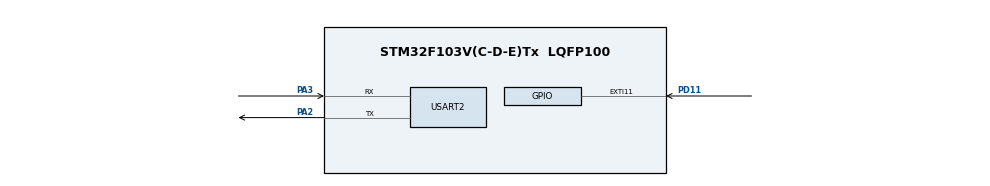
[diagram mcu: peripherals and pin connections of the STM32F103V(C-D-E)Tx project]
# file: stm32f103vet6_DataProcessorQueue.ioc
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FREERTOS.Tasks01=defaultTask,0,128,StartDefaultTask,Default,NULL,Dynamic,NULL,NULL;DataProcessorTa,0,256,StartDataProcessorTask,Default,NULL,Dynamic,NULL,NULL
Mcu.Family=STM32F1
Mcu.Name=STM32F103V(C-D-E)Tx
Mcu.Package=LQFP100
NVIC.EXTI15_10_IRQn=true\:5\:0\:true\:false\:true\:true\:true\:true\:true
NVIC.PriorityGroup=NVIC_PRIORITYGROUP_4
OSC_IN.Mode=HSE-External-Oscillator
OSC_IN.Signal=RCC_OSC_IN
OSC_OUT.Mode=HSE-External-Oscillator
OSC_OUT.Signal=RCC_OSC_OUT
PA13.Mode=Serial_Wire
PA13.Signal=SYS_JTMS-SWDIO
PA14.Mode=Serial_Wire
PA14.Signal=SYS_JTCK-SWCLK
PA2.Mode=Asynchronous
PA2.Signal=USART2_TX
PA3.Mode=Asynchronous
PA3.Signal=USART2_RX
PD11.GPIO_ModeDefaultEXTI=GPIO_MODE_IT_FALLING
PD11.GPIO_PuPd=GPIO_PULLUP
PD11.Signal=GPXTI11
ProjectManager.HeapSize=0x200
ProjectManager.StackSize=0x400
ProjectManager.TargetToolchain=STM32CubeIDE
RCC.APB1Freq_Value=8000000
RCC.APB2Freq_Value=8000000
USART2.VirtualMode=VM_ASYNC
VP_FREERTOS_VS_CMSIS_V1.Mode=CMSIS_V1
board=custom

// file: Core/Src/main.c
/* USER CODE BEGIN Header */
/**
  ******************************************************************************
  * @file           : main.c
  * @brief          : Main program body
  ******************************************************************************
  * @attention
  *
  * Copyright (c) 2026 STMicroelectronics.
  * All rights reserved.
  *
  * This software is licensed under terms that can be found in the LICENSE file
  * in the root directory of this software component.
  * If no LICENSE file comes with this software, it is provided AS-IS.
  *
  ******************************************************************************
  */
/* USER CODE END Header */
#include "main.h"
#include "cmsis_os.h"

/* USER CODE BEGIN Includes */
#include <stdio.h>
#include <string.h>
#include "queue.h"
#include "task.h"
/* USER CODE END Includes */

/* USER CODE BEGIN PTD */
typedef struct
{
    uint32_t event_id;
    uint32_t tick;
} ButtonEvent_t;
/* USER CODE END PTD */

UART_HandleTypeDef huart2;

osThreadId defaultTaskHandle;
osThreadId DataProcessorTaHandle;
/* USER CODE BEGIN PV */
QueueHandle_t ButtonQueueHandle;
volatile uint32_t g_eventCounter = 0;
/* USER CODE END PV */

void SystemClock_Config(void);
static void MX_GPIO_Init(void);
static void MX_USART2_UART_Init(void);
void StartDefaultTask(void const * argument);
void StartDataProcessorTask(void const * argument);

int main(void)
{

  /* MCU Configuration--------------------------------------------------------*/

  /* Reset of all peripherals, Initializes the Flash interface and the Systick. */
  HAL_Init();

  /* Configure the system clock */
  SystemClock_Config();

  /* Initialize all configured peripherals */
  MX_GPIO_Init();
  MX_USART2_UART_Init();

  /* Create the thread(s) */
  /* definition and creation of defaultTask */
  osThreadDef(defaultTask, StartDefaultTask, osPriorityNormal, 0, 128);
  defaultTaskHandle = osThreadCreate(osThread(defaultTask), NULL);

  /* definition and creation of DataProcessorTa */
  osThreadDef(DataProcessorTa, StartDataProcessorTask, osPriorityNormal, 0, 256);
  DataProcessorTaHandle = osThreadCreate(osThread(DataProcessorTa), NULL);

  /* USER CODE BEGIN RTOS_THREADS */
  /* add threads, ... */
  ButtonQueueHandle = xQueueCreate(10, sizeof(ButtonEvent_t));
  if (ButtonQueueHandle == NULL)
  {
      Error_Handler();
  }
  /* USER CODE END RTOS_THREADS */

  /* Start scheduler */
  osKernelStart();

  /* We should never get here as control is now taken by the scheduler */

  /* Infinite loop */
  while (1)
  {

  }
}

void SystemClock_Config(void)
{
  RCC_OscInitTypeDef RCC_OscInitStruct = {0};
  RCC_ClkInitTypeDef RCC_ClkInitStruct = {0};

  /** Initializes the RCC Oscillators according to the specified parameters
  * in the RCC_OscInitTypeDef structure.
  */
  RCC_OscInitStruct.OscillatorType = RCC_OSCILLATORTYPE_HSI;
  RCC_OscInitStruct.HSIState = RCC_HSI_ON;
  RCC_OscInitStruct.HSICalibrationValue = RCC_HSICALIBRATION_DEFAULT;
  RCC_OscInitStruct.PLL.PLLState = RCC_PLL_NONE;
  if (HAL_RCC_OscConfig(&RCC_OscInitStruct) != HAL_OK)
  {
    Error_Handler();
  }

  /** Initializes the CPU, AHB and APB buses clocks
  */
  RCC_ClkInitStruct.ClockType = RCC_CLOCKTYPE_HCLK|RCC_CLOCKTYPE_SYSCLK
                              |RCC_CLOCKTYPE_PCLK1|RCC_CLOCKTYPE_PCLK2;
  RCC_ClkInitStruct.SYSCLKSource = RCC_SYSCLKSOURCE_HSI;
  RCC_ClkInitStruct.AHBCLKDivider = RCC_SYSCLK_DIV1;
  RCC_ClkInitStruct.APB1CLKDivider = RCC_HCLK_DIV1;
  RCC_ClkInitStruct.APB2CLKDivider = RCC_HCLK_DIV1;

  if (HAL_RCC_ClockConfig(&RCC_ClkInitStruct, FLASH_LATENCY_0) != HAL_OK)
  {
    Error_Handler();
  }
}

static void MX_USART2_UART_Init(void)
{

  huart2.Instance = USART2;
  huart2.Init.BaudRate = 115200;
  huart2.Init.WordLength = UART_WORDLENGTH_8B;
  huart2.Init.StopBits = UART_STOPBITS_1;
  huart2.Init.Parity = UART_PARITY_NONE;
  huart2.Init.Mode = UART_MODE_TX_RX;
  huart2.Init.HwFlowCtl = UART_HWCONTROL_NONE;
  huart2.Init.OverSampling = UART_OVERSAMPLING_16;
  if (HAL_UART_Init(&huart2) != HAL_OK)
  {
    Error_Handler();
  }

}

static void MX_GPIO_Init(void)
{
  GPIO_InitTypeDef GPIO_InitStruct = {0};

  /* GPIO Ports Clock Enable */
  __HAL_RCC_GPIOA_CLK_ENABLE();
  __HAL_RCC_GPIOD_CLK_ENABLE();

  /*Configure GPIO pin : PD11 */
  GPIO_InitStruct.Pin = GPIO_PIN_11;
  GPIO_InitStruct.Mode = GPIO_MODE_IT_FALLING;
  GPIO_InitStruct.Pull = GPIO_PULLUP;
  HAL_GPIO_Init(GPIOD, &GPIO_InitStruct);

  /* EXTI interrupt init*/
  HAL_NVIC_SetPriority(EXTI15_10_IRQn, 5, 0);
  HAL_NVIC_EnableIRQ(EXTI15_10_IRQn);

}

/* USER CODE BEGIN 4 */
void HAL_GPIO_EXTI_Callback(uint16_t GPIO_Pin)
{
    if (GPIO_Pin == GPIO_PIN_11)
    {
        static uint32_t last_isr_tick = 0;
        BaseType_t xHigherPriorityTaskWoken = pdFALSE;
        ButtonEvent_t evt;
        uint32_t now = xTaskGetTickCountFromISR();

        if ((now - last_isr_tick) < pdMS_TO_TICKS(50))
        {
            return;
        }
        last_isr_tick = now;

        evt.event_id = ++g_eventCounter;
        evt.tick = now;

        xQueueSendFromISR(ButtonQueueHandle, &evt, &xHigherPriorityTaskWoken);
        portYIELD_FROM_ISR(xHigherPriorityTaskWoken);
    }
}
/* USER CODE END 4 */

void StartDefaultTask(void const * argument)
{
  for(;;)
  {
    osDelay(1);
  }
}

void StartDataProcessorTask(void const * argument)
{
  /* USER CODE BEGIN StartDataProcessorTask */
  /* Infinite loop */
	ButtonEvent_t rxEvent;
	    uint32_t lastTick = 0;
	    uint8_t firstEvent = 1;
	    char msg[100];

	    for(;;)
	    {
	        if (xQueueReceive(ButtonQueueHandle, &rxEvent, portMAX_DELAY) == pdTRUE)
	        {
	            if (firstEvent)
	            {
	                firstEvent = 0;
	                snprintf(msg, sizeof(msg),
	                         "Event %lu at tick %lu, first event\r\n",
	                         rxEvent.event_id,
	                         rxEvent.tick);
	            }
	            else
	            {
	                uint32_t deltaTick = rxEvent.tick - lastTick;
	                uint32_t deltaMs = (deltaTick * 1000U) / configTICK_RATE_HZ;

	                snprintf(msg, sizeof(msg),
	                         "Event %lu at tick %lu, delta = %lu ms\r\n",
	                         rxEvent.event_id,
	                         rxEvent.tick,
	                         deltaMs);
	            }

	            lastTick = rxEvent.tick;
	            HAL_UART_Transmit(&huart2, (uint8_t*)msg, strlen(msg), HAL_MAX_DELAY);
	        }
	    }
  /* USER CODE END StartDataProcessorTask */
}

void Error_Handler(void)
{
  __disable_irq();
  while (1)
  {
  }
}
